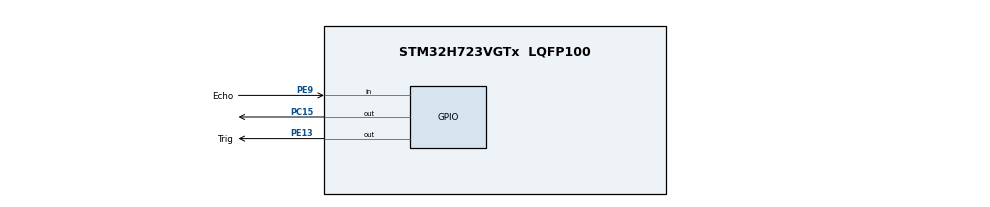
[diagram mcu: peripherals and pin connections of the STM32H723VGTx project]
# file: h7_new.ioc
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CORTEX_M7.default_mode_Activation=1
Mcu.Family=STM32H7
Mcu.Name=STM32H723VGTx
Mcu.Package=LQFP100
NVIC.PriorityGroup=NVIC_PRIORITYGROUP_4
PA13(JTMS/SWDIO).Mode=Serial_Wire
PA13(JTMS/SWDIO).Signal=DEBUG_JTMS-SWDIO
PA14(JTCK/SWCLK).Mode=Serial_Wire
PA14(JTCK/SWCLK).Signal=DEBUG_JTCK-SWCLK
PC15-OSC32_OUT.Signal=GPIO_Output
PE13.GPIO_Label=Trig
PE13.Signal=GPIO_Output
PE9.GPIO_Label=Echo
PE9.Signal=GPIO_Input
PH0-OSC_IN.Mode=HSE-External-Oscillator
PH0-OSC_IN.Signal=RCC_OSC_IN
PH1-OSC_OUT.Mode=HSE-External-Oscillator
PH1-OSC_OUT.Signal=RCC_OSC_OUT
ProjectManager.HeapSize=0x200
ProjectManager.StackSize=0x400
ProjectManager.TargetToolchain=MDK-ARM V5.32
RCC.ADCFreq_Value=129000000
RCC.APB1Freq_Value=137500000
RCC.APB2Freq_Value=137500000
RCC.APB3Freq_Value=137500000
RCC.APB4Freq_Value=137500000
RCC.CortexFreq_Value=275000000
RCC.D1PPRE=RCC_APB3_DIV2
RCC.D2PPRE1=RCC_APB1_DIV2
RCC.D2PPRE2=RCC_APB2_DIV2
RCC.D3PPRE=RCC_APB4_DIV2
RCC.DIVM1=4
RCC.DIVN1=17
RCC.DIVP1=1
RCC.HCLKFreq_Value=275000000
RCC.HSE_VALUE=24000000
RCC.PLL2FRACN=0
RCC.PLL3FRACN=0
RCC.PLLFRACN=1536
RCC.SYSCLKFreq_VALUE=275000000
RCC.SYSCLKSource=RCC_SYSCLKSOURCE_PLLCLK
RCC.USBFreq_Value=137500000
TIM13.Period=1000-1
TIM13.Prescaler=275-1
TIM14.Prescaler=275-1
VP_MEMORYMAP_VS_MEMORYMAP.Mode=CurAppReg
VP_TIM13_VS_ClockSourceINT.Mode=Enable_Timer
VP_TIM14_VS_ClockSourceINT.Mode=Enable_Timer
board=custom

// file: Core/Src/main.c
/* USER CODE BEGIN Header */
/**
  ******************************************************************************
  * @file           : main.c
  * @brief          : Main program body
  ******************************************************************************
  * @attention
  *
  * Copyright (c) 2025 STMicroelectronics.
  * All rights reserved.
  *
  * This software is licensed under terms that can be found in the LICENSE file
  * in the root directory of this software component.
  * If no LICENSE file comes with this software, it is provided AS-IS.
  *
  ******************************************************************************
  */
/* USER CODE END Header */
#include "main.h"
#include "memorymap.h"
#include "tim.h"
#include "gpio.h"

/* USER CODE BEGIN Includes */
#include "delay.h"
/* USER CODE END Includes */

/* USER CODE BEGIN PV */
volatile float distance;
uint8_t state;
uint64_t error_count, success_count, error_count2;

/* USER CODE END PV */

void SystemClock_Config(void);
static void MPU_Config(void);
/* USER CODE BEGIN PFP */
void start_signal(void);
void wait_echo(void);
void compute_distance(void);
/* USER CODE END PFP */

int main(void)
{

  /* MPU Configuration--------------------------------------------------------*/
  MPU_Config();

  /* MCU Configuration--------------------------------------------------------*/

  /* Reset of all peripherals, Initializes the Flash interface and the Systick. */
  HAL_Init();

  /* Configure the system clock */
  SystemClock_Config();

  /* Initialize all configured peripherals */
  MX_GPIO_Init();
  MX_TIM13_Init();
  MX_TIM14_Init();
  /* USER CODE BEGIN 2 */
	delay_init(275);
	HAL_GPIO_WritePin(GPIOC,GPIO_PIN_15,1);
	HAL_Delay(1000);
  /* USER CODE END 2 */

  /* Infinite loop */
  /* USER CODE BEGIN WHILE */
  while (1)
  {
	  //HAL_GPIO_WritePin(Trig_GPIO_Port, Trig_Pin, 1);
	  //HAL_Delay(0);
	  //HAL_GPIO_WritePin(Trig_GPIO_Port, Trig_Pin, 0);
	  //HAL_Delay(0);
	  //
	  switch (state)
	  {
		  case 0:
			  start_signal();//启动信号
			  break;
		  case 1:
				//state = 2;
			  wait_echo();
			  break;
		  case 2:
			  compute_distance();
			  break;
		  default:
			  state = 0;
	  }
    /* USER CODE END WHILE */

  }
}

void SystemClock_Config(void)
{
  RCC_OscInitTypeDef RCC_OscInitStruct = {0};
  RCC_ClkInitTypeDef RCC_ClkInitStruct = {0};

  /** Supply configuration update enable
  */
  HAL_PWREx_ConfigSupply(PWR_LDO_SUPPLY);

  /** Configure the main internal regulator output voltage
  */
  __HAL_PWR_VOLTAGESCALING_CONFIG(PWR_REGULATOR_VOLTAGE_SCALE0);

  while(!__HAL_PWR_GET_FLAG(PWR_FLAG_VOSRDY)) {}

  /** Initializes the RCC Oscillators according to the specified parameters
  * in the RCC_OscInitTypeDef structure.
  */
  RCC_OscInitStruct.OscillatorType = RCC_OSCILLATORTYPE_HSI;
  RCC_OscInitStruct.HSIState = RCC_HSI_DIV1;
  RCC_OscInitStruct.HSICalibrationValue = 64;
  RCC_OscInitStruct.PLL.PLLState = RCC_PLL_ON;
  RCC_OscInitStruct.PLL.PLLSource = RCC_PLLSOURCE_HSI;
  RCC_OscInitStruct.PLL.PLLM = 4;
  RCC_OscInitStruct.PLL.PLLN = 17;
  RCC_OscInitStruct.PLL.PLLP = 1;
  RCC_OscInitStruct.PLL.PLLQ = 2;
  RCC_OscInitStruct.PLL.PLLR = 2;
  RCC_OscInitStruct.PLL.PLLRGE = RCC_PLL1VCIRANGE_3;
  RCC_OscInitStruct.PLL.PLLVCOSEL = RCC_PLL1VCOWIDE;
  RCC_OscInitStruct.PLL.PLLFRACN = 1536;
  if (HAL_RCC_OscConfig(&RCC_OscInitStruct) != HAL_OK)
  {
    Error_Handler();
  }

  /** Initializes the CPU, AHB and APB buses clocks
  */
  RCC_ClkInitStruct.ClockType = RCC_CLOCKTYPE_HCLK|RCC_CLOCKTYPE_SYSCLK
                              |RCC_CLOCKTYPE_PCLK1|RCC_CLOCKTYPE_PCLK2
                              |RCC_CLOCKTYPE_D3PCLK1|RCC_CLOCKTYPE_D1PCLK1;
  RCC_ClkInitStruct.SYSCLKSource = RCC_SYSCLKSOURCE_PLLCLK;
  RCC_ClkInitStruct.SYSCLKDivider = RCC_SYSCLK_DIV1;
  RCC_ClkInitStruct.AHBCLKDivider = RCC_HCLK_DIV1;
  RCC_ClkInitStruct.APB3CLKDivider = RCC_APB3_DIV2;
  RCC_ClkInitStruct.APB1CLKDivider = RCC_APB1_DIV2;
  RCC_ClkInitStruct.APB2CLKDivider = RCC_APB2_DIV2;
  RCC_ClkInitStruct.APB4CLKDivider = RCC_APB4_DIV2;

  if (HAL_RCC_ClockConfig(&RCC_ClkInitStruct, FLASH_LATENCY_3) != HAL_OK)
  {
    Error_Handler();
  }
}

/* USER CODE BEGIN 4 */
void start_signal(void)
{
	HAL_GPIO_WritePin(Trig_GPIO_Port, Trig_Pin, 1);
	delay_us(20);
	HAL_GPIO_WritePin(Trig_GPIO_Port, Trig_Pin, 0);
	state = 1;
}

void wait_echo(void)
{
	uint32_t delay_time = 5;
	uint32_t start_time = HAL_GetTick();//ms级别的计时
	uint32_t cur_time;
	while (((cur_time = HAL_GetTick()) - start_time < delay_time) && (HAL_GPIO_ReadPin(Echo_GPIO_Port, Echo_Pin) == 0)) // 等待1ms，或是超声波响应
	{

	}

	if (cur_time - start_time >= delay_time)//如果是超时退出，则重新启动
	{
		error_count++;
		state = 0;
	}
	else//反之则进入下一步
	{
		state = 2;
		success_count++;
	}
}

// 全局变量定义
uint32_t start_time_ms;
int32_t start_time_us;
uint32_t cur_time_ms;
int32_t cur_time_us;
float echo_time_ms, echo_time_us, echo_time;

void compute_distance(void)
{
	start_time_ms = HAL_GetTick(); // ms级别的计时
	start_time_us = SysTick->VAL;
	while (HAL_GPIO_ReadPin(Echo_GPIO_Port, Echo_Pin)) // 暂时不做保护，因为当前bug主要集中在state=1的地方
	{

	};
	cur_time_ms = HAL_GetTick();
	cur_time_us = SysTick->VAL;
	//echo_time = cur_time_ms - start_time_ms;
	echo_time_ms = cur_time_ms - start_time_ms; // 单位是ms,us也许需要单独处理
	echo_time_us = -(cur_time_us - start_time_us) * 0.001f * 0.00363f;//也是ms单位,因为是向下的计数器，所以应该取反
	//echo_time = (cur_time_us - start_time_us) * 0.001f * 0.00363f; // 单位是ms
	/*
	*	1. 如果ms之差不超过1，即距离小于0.17m，则cur_us必然大于start_us,此时乘以0.00363，转化为us单位，×0.001，转为ms单位
	*		实际推测发现，也不尽是，cur_us = 11601 start_us = 163258,一旦二者相减，出现一个负数，则超出了uint32_t能表达的范围，造成溢出
	*   2. 可以确定，ms级别的计时没有问题，但是分度值在0.17m，太粗了。需要把us级别的计时独立出来，而后必然要封装一个计时函数
	*/
	//if (echo_time_ms == 0.0f && echo_time_us < 0)
	//{
	//	echo_time_us += 1.0f;
	//}
	echo_time = echo_time_ms + echo_time_us; // 单位是ms
	//if (echo_time > 1000.0f)
	//{
	//	error_count2++;
	//}
	// distance = (float)echo_time * 0.001f * 340.0f / 2.0f; // 单位是m
	distance = (float)echo_time * 0.17;
	state = 0;
}
//测试一下git，看样子是端口号的问题，再测试一次，看样子推论是错的，还需要后续慢慢测试，测试一下上传速度。再次测试端口7890.地方
/* USER CODE END 4 */

 /* MPU Configuration */

void MPU_Config(void)
{
  MPU_Region_InitTypeDef MPU_InitStruct = {0};

  /* Disables the MPU */
  HAL_MPU_Disable();

  /** Initializes and configures the Region and the memory to be protected
  */
  MPU_InitStruct.Enable = MPU_REGION_ENABLE;
  MPU_InitStruct.Number = MPU_REGION_NUMBER0;
  MPU_InitStruct.BaseAddress = 0x0;
  MPU_InitStruct.Size = MPU_REGION_SIZE_4GB;
  MPU_InitStruct.SubRegionDisable = 0x87;
  MPU_InitStruct.TypeExtField = MPU_TEX_LEVEL0;
  MPU_InitStruct.AccessPermission = MPU_REGION_NO_ACCESS;
  MPU_InitStruct.DisableExec = MPU_INSTRUCTION_ACCESS_DISABLE;
  MPU_InitStruct.IsShareable = MPU_ACCESS_SHAREABLE;
  MPU_InitStruct.IsCacheable = MPU_ACCESS_NOT_CACHEABLE;
  MPU_InitStruct.IsBufferable = MPU_ACCESS_NOT_BUFFERABLE;

  HAL_MPU_ConfigRegion(&MPU_InitStruct);
  /* Enables the MPU */
  HAL_MPU_Enable(MPU_PRIVILEGED_DEFAULT);

}

void Error_Handler(void)
{
  __disable_irq();
  while (1)
  {
  }
}
